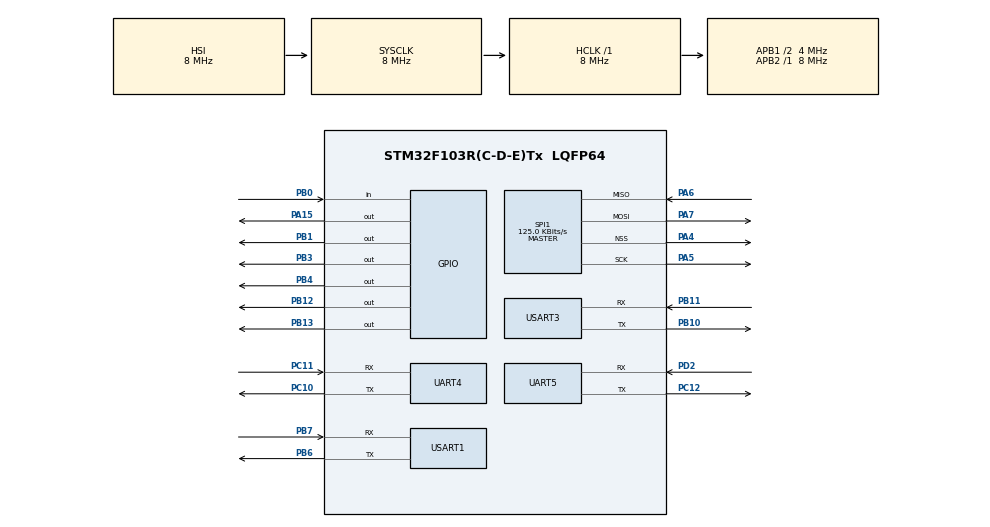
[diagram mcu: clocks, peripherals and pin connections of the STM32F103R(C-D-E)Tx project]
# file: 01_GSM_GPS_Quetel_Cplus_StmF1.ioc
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Mcu.Family=STM32F1
NVIC.USART3_IRQn=true\:0\:0\:false\:false\:true\:true\:true
PA6.Mode=Full_Duplex_Master
NVIC.DMA1_Channel5_IRQn=true\:0\:0\:false\:false\:true\:false\:true
SPI1.VirtualType=VM_MASTER
Dma.USART1_TX.1.MemInc=DMA_MINC_ENABLE
PB10.Mode=Asynchronous
PC10.Signal=UART4_TX
PC12.Signal=UART5_TX
PB11.Signal=USART3_RX
PB13.Signal=GPIO_Output
ProjectManager.StackSize=0x400
NVIC.UART5_IRQn=true\:0\:0\:false\:false\:true\:true\:true
PD1-OSC_OUT.Signal=RCC_OSC_OUT
PA4.Mode=NSS_Signal_Hard_Output
SPI1.Direction=SPI_DIRECTION_2LINES
RCC.HCLKFreq_Value=8000000
RCC.APB2TimFreq_Value=8000000
PB6.Signal=USART1_TX
PB6.Mode=Asynchronous
SPI1.CalculateBaudRate=125.0 KBits/s
RCC.AHBFreq_Value=8000000
Dma.USART1_RX.0.Priority=DMA_PRIORITY_LOW
RCC.PLLMUL=RCC_PLL_MUL9
PA14.Mode=Serial_Wire
PB7.Signal=USART1_RX
SPI1.VirtualNSS=VM_NSSHARD
Dma.USART1_RX.0.MemInc=DMA_MINC_ENABLE
Dma.USART1_TX.1.PeriphDataAlignment=DMA_PDATAALIGN_BYTE
Mcu.Package=LQFP64
PB1.Signal=GPIO_Output
PA6.Signal=SPI1_MISO
PA15.Signal=GPIO_Output
PC11.Mode=Asynchronous
Dma.Request1=USART1_TX
RCC.APB1TimFreq_Value=8000000
Dma.USART1_RX.0.Mode=DMA_CIRCULAR
Dma.USART1_TX.1.Priority=DMA_PRIORITY_LOW
NVIC.DMA1_Channel4_IRQn=true\:0\:0\:false\:false\:true\:false\:true
NVIC.USART1_IRQn=true\:0\:0\:false\:false\:true\:true\:true
Dma.Request0=USART1_RX
SPI1.BaudRatePrescaler=SPI_BAUDRATEPRESCALER_64
Dma.USART1_RX.0.Instance=DMA1_Channel5
PB4.Signal=GPIO_Output
PA5.Mode=Full_Duplex_Master
Dma.USART1_TX.1.Direction=DMA_MEMORY_TO_PERIPH
RCC.PLLSourceVirtual=RCC_PLLSOURCE_HSE
Dma.USART1_TX.1.Instance=DMA1_Channel4
PA7.Mode=Full_Duplex_Master
PD1-OSC_OUT.Mode=HSE-External-Oscillator
Dma.USART1_RX.0.PeriphDataAlignment=DMA_PDATAALIGN_BYTE
PC11.Signal=UART4_RX
PC10.Mode=Asynchronous
PD0-OSC_IN.Signal=RCC_OSC_IN
UART5.VirtualMode=Asynchronous
RCC.APB1CLKDivider=RCC_HCLK_DIV2
UART4.VirtualMode=Asynchronous
PA13.Signal=SYS_JTMS-SWDIO
PB11.Mode=Asynchronous
ProjectManager.TargetToolchain=MDK-ARM V5.27
Dma.USART1_RX.0.Direction=DMA_PERIPH_TO_MEMORY
RCC.USBFreq_Value=72000000
Dma.USART1_RX.0.PeriphInc=DMA_PINC_DISABLE
PB10.Signal=USART3_TX
PD0-OSC_IN.Mode=HSE-External-Oscillator
PD2.Mode=Asynchronous
PA5.Signal=SPI1_SCK
PC12.Mode=Asynchronous
Dma.USART1_TX.1.MemDataAlignment=DMA_MDATAALIGN_BYTE
board=custom
RCC.APB2Freq_Value=8000000
SPI1.Mode=SPI_MODE_MASTER
Dma.USART1_RX.0.MemDataAlignment=DMA_MDATAALIGN_BYTE
PA13.Mode=Serial_Wire
Mcu.Name=STM32F103R(C-D-E)Tx
PB3.Signal=GPIO_Output
PA4.Signal=SPI1_NSS
RCC.SYSCLKFreq_VALUE=8000000
USART3.VirtualMode=VM_ASYNC
Dma.USART1_TX.1.Mode=DMA_NORMAL
USART1.VirtualMode=VM_ASYNC
PB7.Mode=Asynchronous
PA14.Signal=SYS_JTCK-SWCLK
ProjectManager.HeapSize=0x200
Dma.USART1_TX.1.PeriphInc=DMA_PINC_DISABLE
NVIC.PriorityGroup=NVIC_PRIORITYGROUP_4
PD2.Signal=UART5_RX
RCC.APB1Freq_Value=4000000
PB0.Signal=GPIO_Input
PB12.Signal=GPIO_Output
PA7.Signal=SPI1_MOSI

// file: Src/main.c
/* USER CODE BEGIN Header */
/**
  ******************************************************************************
  * @file           : main.c
  * @brief          : Main program body
  ******************************************************************************
  * @attention
  *
  * <h2><center>&copy; Copyright (c) 2020 STMicroelectronics.
  * All rights reserved.</center></h2>
  *
  * This software component is licensed by ST under BSD 3-Clause license,
  * the "License"; You may not use this file except in compliance with the
  * License. You may obtain a copy of the License at:
  *                        opensource.org/licenses/BSD-3-Clause
  *
  ******************************************************************************
  */
/* USER CODE END Header */

#include "main.h"
#include "dma.h"
#include "spi.h"
#include "usart.h"
#include "gpio.h"

/* USER CODE BEGIN Includes */
#include "StateMachine_hh.h"
#include "SerialControl_hh.h"
/* USER CODE END Includes */

void SystemClock_Config(void);

int main(void)
{
  /* USER CODE BEGIN 1 */
//uwTickPrio = TICK_INT_PRIORITY;
  /* USER CODE END 1 */

  /* MCU Configuration--------------------------------------------------------*/

  /* Reset of all peripherals, Initializes the Flash interface and the Systick. */
  HAL_Init();

  /* Configure the system clock */
  SystemClock_Config();

  /* Initialize all configured peripherals */
  MX_GPIO_Init();
  MX_DMA_Init();
  MX_SPI1_Init();
  MX_UART4_Init();
  MX_UART5_Init();
  MX_USART1_UART_Init();
  MX_USART3_UART_Init();
  /* USER CODE BEGIN 2 */
	SerialBegin();
  /* USER CODE END 2 */

  /* Infinite loop */
  /* USER CODE BEGIN WHILE */
  while (1)
  {
		StateMachine();
    /* USER CODE END WHILE */

  }
}

void SystemClock_Config(void)
{
  RCC_OscInitTypeDef RCC_OscInitStruct = {0};
  RCC_ClkInitTypeDef RCC_ClkInitStruct = {0};

  /** Initializes the CPU, AHB and APB busses clocks
  */
  RCC_OscInitStruct.OscillatorType = RCC_OSCILLATORTYPE_HSI;
  RCC_OscInitStruct.HSIState = RCC_HSI_ON;
  RCC_OscInitStruct.HSICalibrationValue = RCC_HSICALIBRATION_DEFAULT;
  RCC_OscInitStruct.PLL.PLLState = RCC_PLL_NONE;
  if (HAL_RCC_OscConfig(&RCC_OscInitStruct) != HAL_OK)
  {
    Error_Handler();
  }
  /** Initializes the CPU, AHB and APB busses clocks
  */
  RCC_ClkInitStruct.ClockType = RCC_CLOCKTYPE_HCLK|RCC_CLOCKTYPE_SYSCLK
                              |RCC_CLOCKTYPE_PCLK1|RCC_CLOCKTYPE_PCLK2;
  RCC_ClkInitStruct.SYSCLKSource = RCC_SYSCLKSOURCE_HSI;
  RCC_ClkInitStruct.AHBCLKDivider = RCC_SYSCLK_DIV1;
  RCC_ClkInitStruct.APB1CLKDivider = RCC_HCLK_DIV2;
  RCC_ClkInitStruct.APB2CLKDivider = RCC_HCLK_DIV1;

  if (HAL_RCC_ClockConfig(&RCC_ClkInitStruct, FLASH_LATENCY_0) != HAL_OK)
  {
    Error_Handler();
  }
}

void Error_Handler(void)
{
}

/************************ (C) COPYRIGHT STMicroelectronics *****END OF FILE****/
